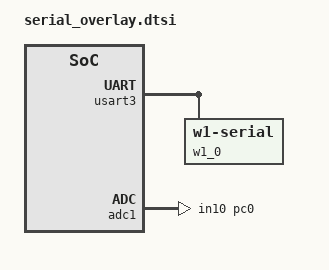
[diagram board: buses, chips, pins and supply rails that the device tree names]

&usart3 {
	status = "okay";

	w1_0: w1-zephyr-serial-0 {
		compatible = "zephyr,w1-serial";
		#address-cells = <1>;
		#size-cells = <0>;
		status = "okay";

		ds18b20 {
			compatible = "maxim,ds18b20";
			family-code = <0x28>;
			resolution = <12>;
			status = "okay";
		};
	};
};

&adc1 {
	pinctrl-0 = <&adc_in10_pc0>;
	pinctrl-names = "default";
	status = "okay";
};


